# APM32F00x register map
File version: 1.0
CPU: CM0+ r0p1, little endian, no MPU, no FPU, 4 interrupt priority bits
Registers are 32-bit, read-write, reset 0x0 unless marked. A register's access mark holds for its fields unless they carry their own. Offsets are from the block's base; [hi:lo] are bit positions; {n}, {i} and the like mark numbered series.

## SPI — Serial peripheral interface
Base 0x40002C00
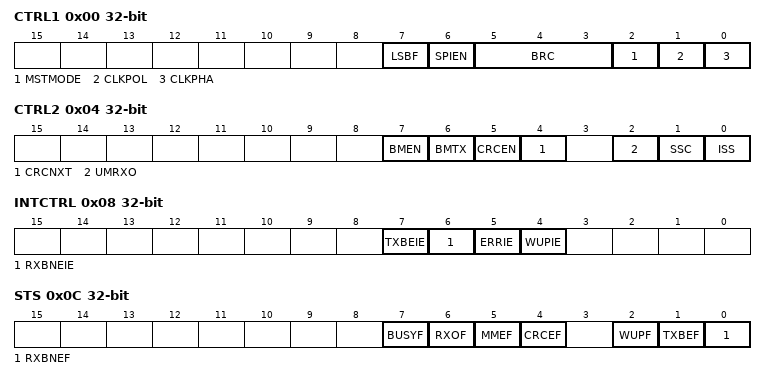
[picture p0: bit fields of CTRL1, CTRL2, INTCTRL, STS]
0x00 CTRL1 — Control register 1
  [7] LSBF — LSB First Transfer Select
  [6] SPIEN — SPI Device Enable
  [5:3] BRC — Baud Rate Divider Factor Selectl
  [2] MSTMODE — Master/Salve Mode Configure
  [1] CLKPOL — Clock Polarity Configure
  [0] CLKPHA — Clock Phase Configure
0x04 CTRL2 — Control register 2
  [7] BMEN — Bidirectional Mode Enable
  [6] BMTX — Bidirectional Mode Output Enable
  [5] CRCEN — CRC Calculate Enable
  [4] CRCNXT — CRC Transfer Next Enable
  [2] UMRXO — Receive Only Mode Enable
  [1] SSC — Software Slave Device Enable
  [0] ISS — Internal Slave Device Select
0x08 INTCTRL — Interrupt control register
  [7] TXBEIE — Transmit Buffer Empty Interrupt Enable
  [6] RXBNEIE — Receive Buffer Not Empty Interrupt Enable
  [5] ERRIE — Error Interrupt Enable
  [4] WUPIE — Wake up Interrupt Enable
0x0C STS — Status register
  [7] BUSYF — SPI Busy Flag
  [6] RXOF — Overrun Occur Flag
  [5] MMEF — Mode Error Occur Flag
  [4] CRCEF — CRC Error Occur Flag
  [2] WUPF — Wake up Event Occur Flag
  [1] TXBEF — Transmit Buffer Empty Flag
  [0] RXBNEF — Receive Buffer Not Empty Flag
0x10 DATA
  [7:0] DATA — Transmit Receive Data register
0x14 CRCPOLY — CRC polynomial register
  [7:0] CRCPOLY — CRC Polynomial Value Setup
0x18 RXCRC ro
  [7:0] RXCRC — Receive Data CRC Value
0x20 TXCRC ro
  [7:0] TXCRC — Transmit Data CRC Value

## ADC — Analog to digital converter
Base 0x40004400
{0x0+8i} DATABUF{i}H ro (i=0..9) — Data buffer {2i}
  [7:0] DATABUF{2i} — Regular data {2i}
{0x4+8i} DATABUF{i}L ro (i=0..9) — Data buffer {2i+1}
  [7:0] DATABUF{2i+1} — Regular data {2i+1}
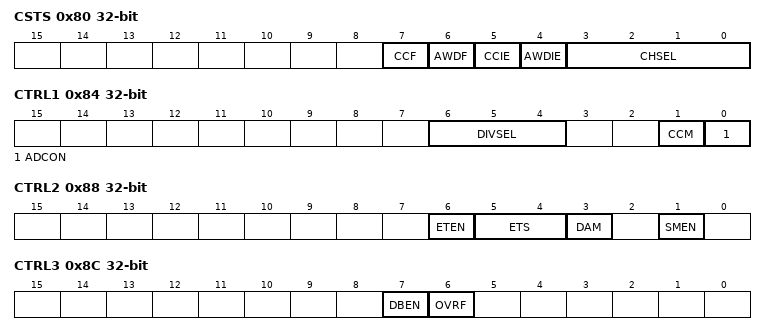
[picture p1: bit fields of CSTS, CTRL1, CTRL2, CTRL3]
0x80 CSTS — control/status register
  [7] CCF — End Of Conversion Flag
  [6] AWDF — Analog Watchdog Occur Flag
  [5] CCIE — End Of Conversion Interrupt Enable
  [4] AWDIE — Analog Watchdog Interrupt Enable
  [3:0] CHSEL — Conversion Channel Select
0x84 CTRL1 — control register 1
  [6:4] DIVSEL — Prescaler Select
  [1] CCM — Continuous Conversion Mode Enable
  [0] ADCON — ADC Enable
0x88 CTRL2 — control register 2
  [6] ETEN — External Trigger Enable
  [5:4] ETS — External Trigger Event Select
  [3] DAM — Data Alignment Mode Configure
  [1] SMEN — Scan Mode Enable
0x8C CTRL3 — control register 3
  [7] DBEN — Data Butter Enable
  [6] OVRF — Overrun Flag
0x90 DATA1 ro — high-regular data register
  [7:0] DATA — ADC Conversion High Data
0x94 DATA0 ro — low-regular data register
  [7:0] DATA — ADC Conversion Low Data
0x98 STD1 — Schmitt trigger disable register high
  [7:0] STD — Schmitt trigger prohibit high
0x9C STD0 — Schmitt trigger disable register low
  [7:0] STD — Schmitt trigger prohibit low
0xA0 AWDHT1 reset 0xFFF — watchdog higher threshold register high
  [7:0] AWDHT — Analog watchdog higher threshold high
0xA4 AWDHT0 reset 0x3 — watchdog higher threshold register low
  [7:0] AWDHT — Analog watchdog higher threshold low
0xA8 AWDLT1 — watchdog lower threshold register high
  [7:0] AWDLT — Analog watchdog lower threshold high
0xAC AWDLT0 — watchdog lower threshold register low
  [7:0] AWDLT — Analog watchdog lower threshold low
0xB0 AWDS1 — Watchdog status high register
  [1:0] AWDS — Watchdog status register
0xB4 AWDS0 — Watchdog status low register
  [7:0] AWDS — Watchdog status register
0xB8 AWDEN1 — Watchdog Control high register
  [1:0] AWDEN — Watchdog Control egister
0xBC AWDEN0 — Watchdog Control low register
  [7:0] AWDEN — Watchdog Control egister
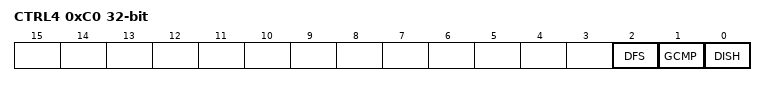
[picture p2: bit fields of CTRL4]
0xC0 CTRL4 — Control register 4
  [2] DFS — Input Mode Select
  [1] GCMP — Internal Delay Time Select
  [0] DISH — Differential Input Calibration
0xC4 OFFSET
  [5:0] OFFSET — Offset Configure

## EINT — External interrupt control
Base 0x40001800
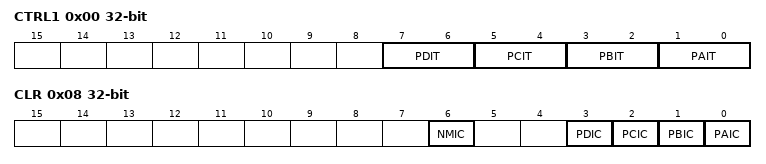
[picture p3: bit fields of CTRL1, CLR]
0x00 CTRL1 — External Interrupt Control Register for PORTA to PORTD
  [7:6] PDIT — PORTD external interrupt sensitivity bits mask
  [5:4] PCIT — PORTC external interrupt sensitivity bits mask
  [3:2] PBIT — PORTB external interrupt sensitivity bits mask
  [1:0] PAIT — PORTA external interrupt sensitivity bits mask
0x04 CTRL2 — External Interrupt Control Register for PORTE and TLI
  [2] NMIT
0x08 CLR write — External interrupt clear register
  [6] NMIC, [3] PDIC, [2] PCIC, [1] PBIC, [0] PAIC

## IWDT — Independent Watchdog
Base 0x40002000
0x00 KEYWORD wo — Key Register
  [7:0] KEY
0x04 PSC — Prescaler Register
  [2:0] PSC
0x08 CNTRLD write reset 0xFF — Reload Register
  [7:0] CNTRLD

## WWDT — Window Watchdog
Base 0x40001C00
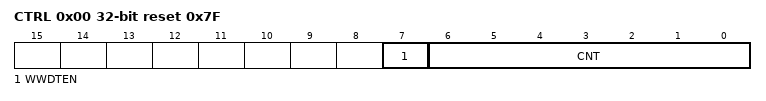
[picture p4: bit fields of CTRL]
0x00 CTRL reset 0x7F — Control Register
  [7] WWDTEN — Window Watchdog Enable
  [6:0] CNT — Counter Value Setup
0x04 WDDATA reset 0x7F — Window Register
  [6:0] WINCNT — Window Value Setup

## BUZZER — Beeper
Base 0x40002800
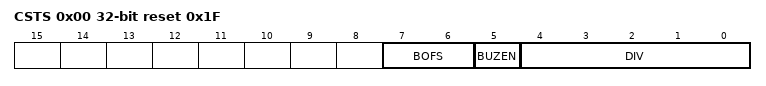
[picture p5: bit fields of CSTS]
0x00 CSTS reset 0x1F — External Interrupt Control Register for PORTA to PORTD
  [7:6] BOFS — Beeper frequency selection mask
  [5] BUZEN — Beeper enable mask
  [4:0] DIV — Beeper Divider prescalar mask

## WUPT — Auto wake up
Base 0x40002400
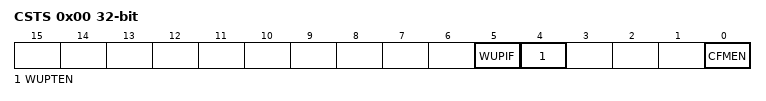
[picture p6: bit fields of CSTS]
0x00 CSTS — WUPT Control status register
  [5] WUPIF — Interrupt flag mask
  [4] WUPTEN — Auto Wake-up enable mask
  [0] CFMEN — LSI Measurement enable mask
0x04 DIV reset 0x3F — WUPT Asynchronous prescaler buffer
  [5:0] DIV — Asynchronous Prescaler divider mask
0x08 TBC write — WUPT Time base selection register
  [3:0] TBC — Timebase selection mask

## FMC — Flash Interface
Base 0x40011000
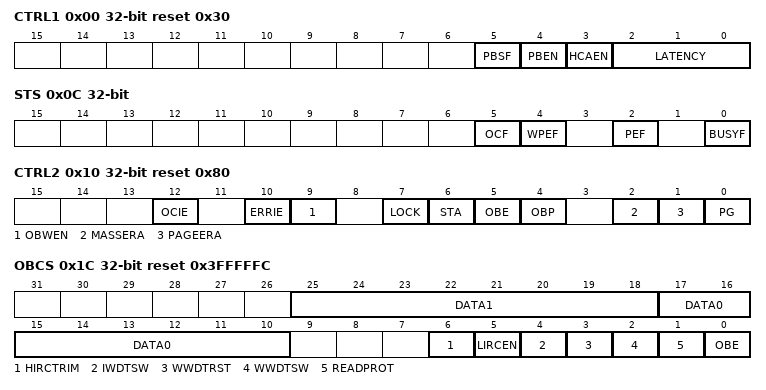
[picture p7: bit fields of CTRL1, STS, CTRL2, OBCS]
0x00 CTRL1 access per field reset 0x30 — Flash access control register
  [5] PBSF ro — Prefetch buffer status
  [4] PBEN rw — Prefetch buffer enable
  [3] HCAEN rw — Flash half cycle access enable
  [2:0] LATENCY rw
0x04 KEY wo — Flash key register
  [31:0] KEY — FMC key
0x08 OBKEY wo — Flash option key register
  [31:0] OBEYR — Option byte key
0x0C STS access per field — Status register
  [5] OCF rw — End of operation
  [4] WPEF rw — Write protection error
  [2] PEF rw — Programming error
  [0] BUSYF ro
0x10 CTRL2 reset 0x80 — Control register
  [12] OCIE — End of operation interrupt enable
  [10] ERRIE — Error interrupt enable
  [9] OBWEN — Option bytes write enable
  [7] LOCK
  [6] STA — Start
  [5] OBE — Option byte erase
  [4] OBP — Option byte programming
  [2] MASSERA — Mass Erase
  [1] PAGEERA — Page Erase
  [0] PG — Programming
0x14 ADDR wo — Flash address register
  [31:0] ADDR — Flash Address
0x1C OBCS ro reset 0x3FFFFFC — Option byte register
  [25:18] DATA1
  [17:10] DATA0
  [6] HIRCTRIM
  [5] LIRCEN — LIRC Enable
  [4] IWDTSW — IWDT Switch
  [3] WWDTRST — WWDT Reset
  [2] WWDTSW — WWDT Switch
  [1] READPROT — Read Protect
  [0] OBE — Option Byte Error
0x20 WRTPROT ro reset 0xFFFFFFFF — Write protection register
  [31:0] WRTPROT — Write protect
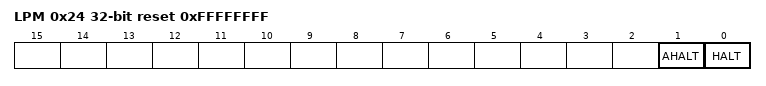
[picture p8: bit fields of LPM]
0x24 LPM reset 0xFFFFFFFF — Low power mode register
  [1] AHALT — Power-down in Halt mode
  [0] HALT — Power-down in Active-Halt mode
0x28 TPO reset 0xFFFFFFFF — tpower_on register
  [7:0] TPO — The tsu of Flash in Power-downwmode

## OB — Option Bytes Registers
Base 0x00020400
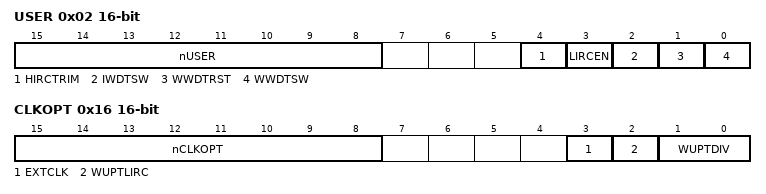
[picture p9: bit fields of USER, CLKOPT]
0x02 USER 16-bit
  [15:8] nUSER, [4] HIRCTRIM, [3] LIRCEN, [2] IWDTSW, [1] WWDTRST, [0] WWDTSW
0x04 DATA0 16-bit wo
0x06 DATA1 16-bit wo
{0x8+2i} WRTPROT{i} 16-bit (i=0..3)
0x10 AFR 16-bit
0x14 HXTCNT 16-bit
0x16 CLKOPT 16-bit
  [15:8] nCLKOPT, [3] EXTCLK, [2] WUPTLIRC, [1:0] WUPTDIV
